# ESP32-S31 register map
Vendor: ESPRESSIF SYSTEMS (SHANGHAI) CO., LTD.; Series: ESP32 S-Series; File version: 1
CPU: RV32IMAFC r0p0, little endian, no MPU, FPU, 0 interrupt priority bits
Address unit: 32 bits
Registers are 32-bit, read-write, reset 0x0 unless marked. A register's access mark holds for its fields unless they carry their own. Offsets are from the block's base; [hi:lo] are bit positions.

## CACHE (part 1 of 3) — CACHE Peripheral
Base 0x2C000000
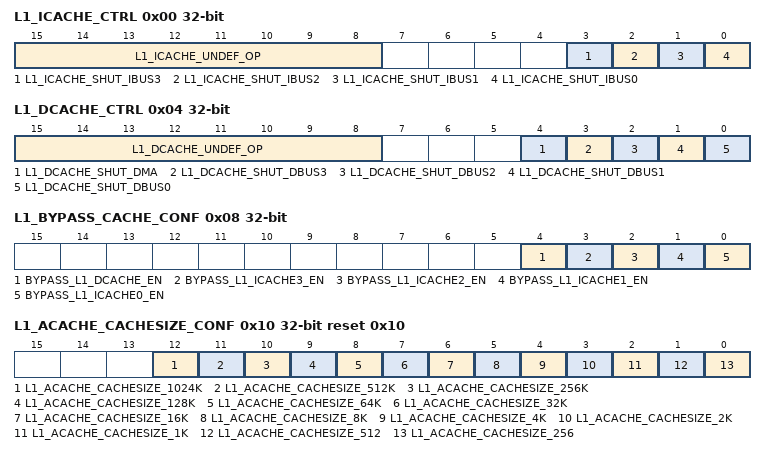
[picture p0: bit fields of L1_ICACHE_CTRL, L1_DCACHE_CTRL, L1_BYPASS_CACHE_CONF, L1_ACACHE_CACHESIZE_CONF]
0x00 L1_ICACHE_CTRL — L1 instruction Cache(L1-ICache) control register
  [15:8] L1_ICACHE_UNDEF_OP — Reserved
  [3] L1_ICACHE_SHUT_IBUS3 — Configures whether to disable IBUS3 to access ROM cache.\\1: Disable\\
  [2] L1_ICACHE_SHUT_IBUS2 — Configures whether to disable IBUS2 to access ROM cache.\\1: Disable\\
  [1] L1_ICACHE_SHUT_IBUS1 — Configures whether to disable IBUS1 to access icache.\\1: Disable\\
  [0] L1_ICACHE_SHUT_IBUS0 — Configures whether to disable IBUS0 to access icache.\\1: Disable\\
0x04 L1_DCACHE_CTRL — L1 data Cache(L1-DCache) control register
  [15:8] L1_DCACHE_UNDEF_OP — Reserved
  [4] L1_DCACHE_SHUT_DMA — The bit is used to disable DMA access L1-DCache, 0: enable, 1: disable
  [3] L1_DCACHE_SHUT_DBUS3 — Configures whether to disable DBUS3 to access ROM cache.\\1: Disable\\
  [2] L1_DCACHE_SHUT_DBUS2 — Configures whether to disable DBUS2 to access ROM cache.\\1: Disable\\
  [1] L1_DCACHE_SHUT_DBUS1 — Configures whether to disable DBUS1 to access dcache.\\1: Disable\\
  [0] L1_DCACHE_SHUT_DBUS0 — Configures whether to disable DBUS0 to access dcache.\\1: Disable\\
0x08 L1_BYPASS_CACHE_CONF — Bypass Cache configure register
  [4] BYPASS_L1_DCACHE_EN — Configures bypass L1-DCache. \\1: Enable\\
  [3] BYPASS_L1_ICACHE3_EN — Reserved
  [2] BYPASS_L1_ICACHE2_EN — Reserved
  [1] BYPASS_L1_ICACHE1_EN — Configures bypass L1-ICache1. \\1: Enable\\
  [0] BYPASS_L1_ICACHE0_EN — Configures bypass L1-ICache0. \\1: Enable\\
0x0C L1_CACHE_ATOMIC_CONF reset 0x1 — L1 Cache atomic feature configure register
  [0] L1_DCACHE_ATOMIC_EN — Configures atomic feature on L1-DCache when multiple cores access L1-DCache. \\1: Enable\\
0x10 L1_ACACHE_CACHESIZE_CONF ro reset 0x10 — L1 Auxiliary Cache CacheSize mode configure register
  [12] L1_ACACHE_CACHESIZE_1024K — The field is used to configure cachesize of L1-ACache as 1024k bytes. This field and all other fields within this register is onehot.
  [11] L1_ACACHE_CACHESIZE_512K — The field is used to configure cachesize of L1-ACache as 512k bytes. This field and all other fields within this register is onehot.
  [10] L1_ACACHE_CACHESIZE_256K — The field is used to configure cachesize of L1-ACache as 256k bytes. This field and all other fields within this register is onehot.
  [9] L1_ACACHE_CACHESIZE_128K — The field is used to configure cachesize of L1-ACache as 128k bytes. This field and all other fields within this register is onehot.
  [8] L1_ACACHE_CACHESIZE_64K — The field is used to configure cachesize of L1-ACache as 64k bytes. This field and all other fields within this register is onehot.
  [7] L1_ACACHE_CACHESIZE_32K — The field is used to configure cachesize of L1-ACache as 32k bytes. This field and all other fields within this register is onehot.
  [6] L1_ACACHE_CACHESIZE_16K — The field is used to configure cachesize of L1-ACache as 16k bytes. This field and all other fields within this register is onehot.
  [5] L1_ACACHE_CACHESIZE_8K — The field is used to configure cachesize of L1-ACache as 8k bytes. This field and all other fields within this register is onehot.
  [4] L1_ACACHE_CACHESIZE_4K — The field is used to configure cachesize of L1-ACache as 4k bytes. This field and all other fields within this register is onehot.
  [3] L1_ACACHE_CACHESIZE_2K — The field is used to configure cachesize of L1-ACache as 2k bytes. This field and all other fields within this register is onehot.
  [2] L1_ACACHE_CACHESIZE_1K — The field is used to configure cachesize of L1-ACache as 1k bytes. This field and all other fields within this register is onehot.
  [1] L1_ACACHE_CACHESIZE_512 — The field is used to configure cachesize of L1-ACache as 512 bytes. This field and all other fields within this register is onehot.
  [0] L1_ACACHE_CACHESIZE_256 — The field is used to configure cachesize of L1-ACache as 256 bytes. This field and all other fields within this register is onehot.
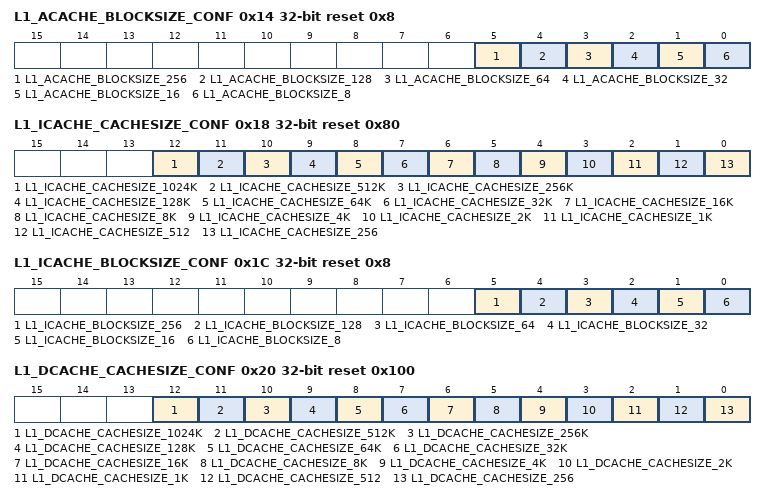
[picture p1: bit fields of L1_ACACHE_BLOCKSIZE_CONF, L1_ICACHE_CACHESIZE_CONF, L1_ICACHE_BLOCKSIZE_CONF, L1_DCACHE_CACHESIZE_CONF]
0x14 L1_ACACHE_BLOCKSIZE_CONF ro reset 0x8 — L1 Auxiliary Cache BlockSize mode configure register
  [5] L1_ACACHE_BLOCKSIZE_256 — The field is used to configureblocksize of L1-ACache as 256 bytes. This field and all other fields within this register is onehot.
  [4] L1_ACACHE_BLOCKSIZE_128 — The field is used to configureblocksize of L1-ACache as 128 bytes. This field and all other fields within this register is onehot.
  [3] L1_ACACHE_BLOCKSIZE_64 — The field is used to configureblocksize of L1-ACache as 64 bytes. This field and all other fields within this register is onehot.
  [2] L1_ACACHE_BLOCKSIZE_32 — The field is used to configureblocksize of L1-ACache as 32 bytes. This field and all other fields within this register is onehot.
  [1] L1_ACACHE_BLOCKSIZE_16 — The field is used to configureblocksize of L1-ACache as 16 bytes. This field and all other fields within this register is onehot.
  [0] L1_ACACHE_BLOCKSIZE_8 — The field is used to configureblocksize of L1-ACache as 8 bytes. This field and all other fields within this register is onehot.
0x18 L1_ICACHE_CACHESIZE_CONF ro reset 0x80 — L1 instruction Cache CacheSize mode configure register
  [12] L1_ICACHE_CACHESIZE_1024K — The field is used to configure cachesize of L1-ICache as 1024k bytes. This field and all other fields within this register is onehot.
  [11] L1_ICACHE_CACHESIZE_512K — The field is used to configure cachesize of L1-ICache as 512k bytes. This field and all other fields within this register is onehot.
  [10] L1_ICACHE_CACHESIZE_256K — The field is used to configure cachesize of L1-ICache as 256k bytes. This field and all other fields within this register is onehot.
  [9] L1_ICACHE_CACHESIZE_128K — The field is used to configure cachesize of L1-ICache as 128k bytes. This field and all other fields within this register is onehot.
  [8] L1_ICACHE_CACHESIZE_64K — The field is used to configure cachesize of L1-ICache as 64k bytes. This field and all other fields within this register is onehot.
  [7] L1_ICACHE_CACHESIZE_32K — The field is used to configure cachesize of L1-ICache as 32k bytes. This field and all other fields within this register is onehot.
  [6] L1_ICACHE_CACHESIZE_16K — The field is used to configure cachesize of L1-ICache as 16k bytes. This field and all other fields within this register is onehot.
  [5] L1_ICACHE_CACHESIZE_8K — The field is used to configure cachesize of L1-ICache as 8k bytes. This field and all other fields within this register is onehot.
  [4] L1_ICACHE_CACHESIZE_4K — The field is used to configure cachesize of L1-ICache as 4k bytes. This field and all other fields within this register is onehot.
  [3] L1_ICACHE_CACHESIZE_2K — The field is used to configure cachesize of L1-ICache as 2k bytes. This field and all other fields within this register is onehot.
  [2] L1_ICACHE_CACHESIZE_1K — The field is used to configure cachesize of L1-ICache as 1k bytes. This field and all other fields within this register is onehot.
  [1] L1_ICACHE_CACHESIZE_512 — The field is used to configure cachesize of L1-ICache as 512 bytes. This field and all other fields within this register is onehot.
  [0] L1_ICACHE_CACHESIZE_256 — The field is used to configure cachesize of L1-ICache as 256 bytes. This field and all other fields within this register is onehot.
0x1C L1_ICACHE_BLOCKSIZE_CONF ro reset 0x8 — L1 instruction Cache BlockSize mode configure register
  [5] L1_ICACHE_BLOCKSIZE_256 — The field is used to configureblocksize of L1-ICache as 256 bytes. This field and all other fields within this register is onehot.
  [4] L1_ICACHE_BLOCKSIZE_128 — The field is used to configureblocksize of L1-ICache as 128 bytes. This field and all other fields within this register is onehot.
  [3] L1_ICACHE_BLOCKSIZE_64 — The field is used to configureblocksize of L1-ICache as 64 bytes. This field and all other fields within this register is onehot.
  [2] L1_ICACHE_BLOCKSIZE_32 — The field is used to configureblocksize of L1-ICache as 32 bytes. This field and all other fields within this register is onehot.
  [1] L1_ICACHE_BLOCKSIZE_16 — The field is used to configureblocksize of L1-ICache as 16 bytes. This field and all other fields within this register is onehot.
  [0] L1_ICACHE_BLOCKSIZE_8 — The field is used to configureblocksize of L1-ICache as 8 bytes. This field and all other fields within this register is onehot.
0x20 L1_DCACHE_CACHESIZE_CONF ro reset 0x100 — L1 data Cache CacheSize mode configure register
  [12] L1_DCACHE_CACHESIZE_1024K — The field is used to configure cachesize of L1-DCache as 1024k bytes. This field and all other fields within this register is onehot.
  [11] L1_DCACHE_CACHESIZE_512K — The field is used to configure cachesize of L1-DCache as 512k bytes. This field and all other fields within this register is onehot.
  [10] L1_DCACHE_CACHESIZE_256K — The field is used to configure cachesize of L1-DCache as 256k bytes. This field and all other fields within this register is onehot.
  [9] L1_DCACHE_CACHESIZE_128K — The field is used to configure cachesize of L1-DCache as 128k bytes. This field and all other fields within this register is onehot.
  [8] L1_DCACHE_CACHESIZE_64K — The field is used to configure cachesize of L1-DCache as 64k bytes. This field and all other fields within this register is onehot.
  [7] L1_DCACHE_CACHESIZE_32K — The field is used to configure cachesize of L1-DCache as 32k bytes. This field and all other fields within this register is onehot.
  [6] L1_DCACHE_CACHESIZE_16K — The field is used to configure cachesize of L1-DCache as 16k bytes. This field and all other fields within this register is onehot.
  [5] L1_DCACHE_CACHESIZE_8K — The field is used to configure cachesize of L1-DCache as 8k bytes. This field and all other fields within this register is onehot.
  [4] L1_DCACHE_CACHESIZE_4K — The field is used to configure cachesize of L1-DCache as 4k bytes. This field and all other fields within this register is onehot.
  [3] L1_DCACHE_CACHESIZE_2K — The field is used to configure cachesize of L1-DCache as 2k bytes. This field and all other fields within this register is onehot.
  [2] L1_DCACHE_CACHESIZE_1K — The field is used to configure cachesize of L1-DCache as 1k bytes. This field and all other fields within this register is onehot.
  [1] L1_DCACHE_CACHESIZE_512 — The field is used to configure cachesize of L1-DCache as 512 bytes. This field and all other fields within this register is onehot.
  [0] L1_DCACHE_CACHESIZE_256 — The field is used to configure cachesize of L1-DCache as 256 bytes. This field and all other fields within this register is onehot.
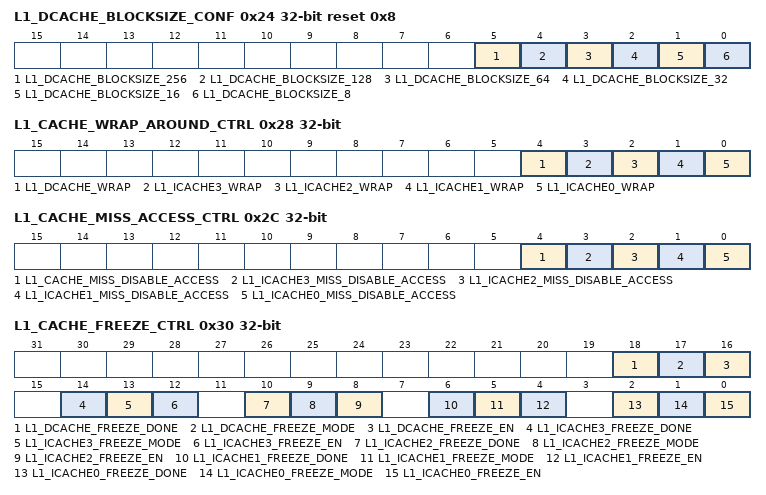
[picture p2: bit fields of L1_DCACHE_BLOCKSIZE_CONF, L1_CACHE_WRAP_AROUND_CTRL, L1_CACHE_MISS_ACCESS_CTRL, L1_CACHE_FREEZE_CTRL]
0x24 L1_DCACHE_BLOCKSIZE_CONF ro reset 0x8 — L1 data Cache BlockSize mode configure register
  [5] L1_DCACHE_BLOCKSIZE_256 — The field is used to configureblocksize of L1-DCache as 256 bytes. This field and all other fields within this register is onehot.
  [4] L1_DCACHE_BLOCKSIZE_128 — The field is used to configureblocksize of L1-DCache as 128 bytes. This field and all other fields within this register is onehot.
  [3] L1_DCACHE_BLOCKSIZE_64 — The field is used to configureblocksize of L1-DCache as 64 bytes. This field and all other fields within this register is onehot.
  [2] L1_DCACHE_BLOCKSIZE_32 — The field is used to configureblocksize of L1-DCache as 32 bytes. This field and all other fields within this register is onehot.
  [1] L1_DCACHE_BLOCKSIZE_16 — The field is used to configureblocksize of L1-DCache as 16 bytes. This field and all other fields within this register is onehot.
  [0] L1_DCACHE_BLOCKSIZE_8 — The field is used to configureblocksize of L1-DCache as 8 bytes. This field and all other fields within this register is onehot.
0x28 L1_CACHE_WRAP_AROUND_CTRL access per field — Cache wrap around control register
  [4] L1_DCACHE_WRAP rw — Configures whether to enable the critical word first function.\\1: Enable\\
  [3] L1_ICACHE3_WRAP ro — Reserved
  [2] L1_ICACHE2_WRAP ro — Reserved
  [1] L1_ICACHE1_WRAP rw — Configures whether to enable the critical word first function.\\1: Enable\\
  [0] L1_ICACHE0_WRAP rw — Configures whether to enable the critical word first function.\\1: Enable\\
0x2C L1_CACHE_MISS_ACCESS_CTRL — Cache wrap around control register
  [4] L1_CACHE_MISS_DISABLE_ACCESS — Configures whether to enable early restart function.\\1: Enable\\
  [3] L1_ICACHE3_MISS_DISABLE_ACCESS — Reserved
  [2] L1_ICACHE2_MISS_DISABLE_ACCESS — Reserved
  [1] L1_ICACHE1_MISS_DISABLE_ACCESS — Configures whether to enable early restart function.\\1: Enable\\
  [0] L1_ICACHE0_MISS_DISABLE_ACCESS — Configures whether to enable early restart function.\\1: Enable\\
0x30 L1_CACHE_FREEZE_CTRL access per field — Cache Freeze control register
  [18] L1_DCACHE_FREEZE_DONE ro — Indicates whether the freeze operation has finished.\\1: Finished\\
  [17] L1_DCACHE_FREEZE_MODE rw — Configures the freeze mode.\\1: Assert hit if a cache miss occurs\\
  [16] L1_DCACHE_FREEZE_EN rw — Configures whether to enable freeze operation. It can be cleared by software.\\1: Enable\\
  [14] L1_ICACHE3_FREEZE_DONE ro — Reserved
  [13] L1_ICACHE3_FREEZE_MODE ro — Reserved
  [12] L1_ICACHE3_FREEZE_EN ro — Reserved
  [10] L1_ICACHE2_FREEZE_DONE ro — Reserved
  [9] L1_ICACHE2_FREEZE_MODE ro — Reserved
  [8] L1_ICACHE2_FREEZE_EN ro — Reserved
  [6] L1_ICACHE1_FREEZE_DONE ro — Indicates whether the freeze operation has finished.\\1: Finished\\
  [5] L1_ICACHE1_FREEZE_MODE rw — Configures the freeze mode.\\1: Assert hit if a cache miss occurs\\
  [4] L1_ICACHE1_FREEZE_EN rw — Configures whether to enable freeze operation. It can be cleared by software.\\1: Enable\\
  [2] L1_ICACHE0_FREEZE_DONE ro — Indicates whether the freeze operation has finished.\\1: Finished\\
  [1] L1_ICACHE0_FREEZE_MODE rw — Configures the freeze mode.\\1: Assert hit if a cache miss occurs\\
  [0] L1_ICACHE0_FREEZE_EN rw — Configures whether to enable freeze operation. It can be cleared by software.\\1: Enable\\
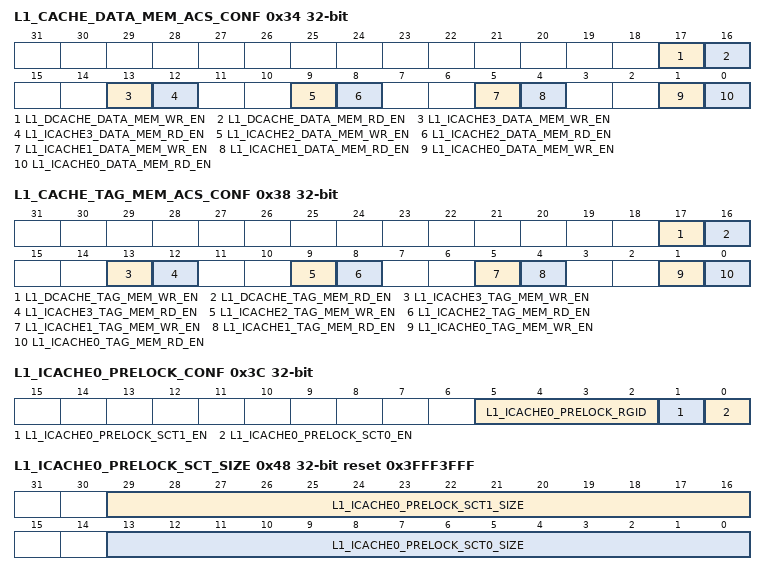
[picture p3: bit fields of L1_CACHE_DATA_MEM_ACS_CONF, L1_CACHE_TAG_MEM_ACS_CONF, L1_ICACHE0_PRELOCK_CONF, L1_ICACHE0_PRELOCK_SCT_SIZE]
0x34 L1_CACHE_DATA_MEM_ACS_CONF — Cache data memory access configure register
  [17] L1_DCACHE_DATA_MEM_WR_EN — Configures whether to enable the configuration bus to write the L1 cache data memory.\\1: Enable\\
  [16] L1_DCACHE_DATA_MEM_RD_EN — Configures whether to enable the configuration bus to read the L1 cache data memory.\\1: Enable\\
  [13] L1_ICACHE3_DATA_MEM_WR_EN — Reserved
  [12] L1_ICACHE3_DATA_MEM_RD_EN — Reserved
  [9] L1_ICACHE2_DATA_MEM_WR_EN — Reserved
  [8] L1_ICACHE2_DATA_MEM_RD_EN — Reserved
  [5] L1_ICACHE1_DATA_MEM_WR_EN — Configures whether to enable the configuration bus to write the L1 cache data memory.\\1: Enable\\
  [4] L1_ICACHE1_DATA_MEM_RD_EN — Configures whether to enable the configuration bus to read the L1 cache data memory.\\1: Enable\\
  [1] L1_ICACHE0_DATA_MEM_WR_EN — Configures whether to enable the configuration bus to write the L1 cache data memory.\\1: Enable\\
  [0] L1_ICACHE0_DATA_MEM_RD_EN — Configures whether to enable the configuration bus to read the L1 cache data memory.\\1: Enable\\
0x38 L1_CACHE_TAG_MEM_ACS_CONF — Cache tag memory access configure register
  [17] L1_DCACHE_TAG_MEM_WR_EN — Configures whether to enable the configuration bus to write the L1 cache tag memory.\\1: Enable\\
  [16] L1_DCACHE_TAG_MEM_RD_EN — Configures whether to enable the configuration bus to read the L1 cache tag memory.\\1: Enable\\
  [13] L1_ICACHE3_TAG_MEM_WR_EN — Reserved
  [12] L1_ICACHE3_TAG_MEM_RD_EN — Reserved
  [9] L1_ICACHE2_TAG_MEM_WR_EN — Reserved
  [8] L1_ICACHE2_TAG_MEM_RD_EN — Reserved
  [5] L1_ICACHE1_TAG_MEM_WR_EN — Configures whether to enable the configuration bus to write the L1 cache tag memory.\\1: Enable\\
  [4] L1_ICACHE1_TAG_MEM_RD_EN — Configures whether to enable the configuration bus to read the L1 cache tag memory.\\1: Enable\\
  [1] L1_ICACHE0_TAG_MEM_WR_EN — Configures whether to enable the configuration bus to write the L1 cache tag memory.\\1: Enable\\
  [0] L1_ICACHE0_TAG_MEM_RD_EN — Configures whether to enable the configuration bus to read the L1 cache tag memory.\\1: Enable\\
0x3C L1_ICACHE0_PRELOCK_CONF — L1 instruction Cache 0 prelock configure register
  [5:2] L1_ICACHE0_PRELOCK_RGID — Configures the gid of l1 icache0 prelock.
  [1] L1_ICACHE0_PRELOCK_SCT1_EN — Configures whether to enable the prelocking function in Section 1 of icache.\\1: Enable\\
  [0] L1_ICACHE0_PRELOCK_SCT0_EN — Configures whether to enable the prelocking function in Section 0 of icache.\\1: Enable\\
0x40 L1_ICACHE0_PRELOCK_SCT0_ADDR — L1 instruction Cache 0 prelock section0 address configure register
  [31:0] L1_ICACHE0_PRELOCK_SCT0_ADDR — Configures the start address of the first section of prelock on L1-ICache0, which should be used together with L1_ICACHE0_PRELOCK_SCT0_SIZE_REG
0x44 L1_ICACHE0_PRELOCK_SCT1_ADDR — L1 instruction Cache 0 prelock section1 address configure register
  [31:0] L1_ICACHE0_PRELOCK_SCT1_ADDR — Configures the start address of the second section of prelock on L1-ICache0, which should be used together with L1_ICACHE0_PRELOCK_SCT1_SIZE_REG
0x48 L1_ICACHE0_PRELOCK_SCT_SIZE reset 0x3FFF3FFF — L1 instruction Cache 0 prelock section size configure register
  [29:16] L1_ICACHE0_PRELOCK_SCT1_SIZE — Configures the size of the second section of prelock on L1-ICache0, which should be used together with L1_ICACHE0_PRELOCK_SCT1_ADDR_REG
  [13:0] L1_ICACHE0_PRELOCK_SCT0_SIZE — Configures the size of the first section of prelock on L1-ICache0, which should be used together with L1_ICACHE0_PRELOCK_SCT0_ADDR_REG
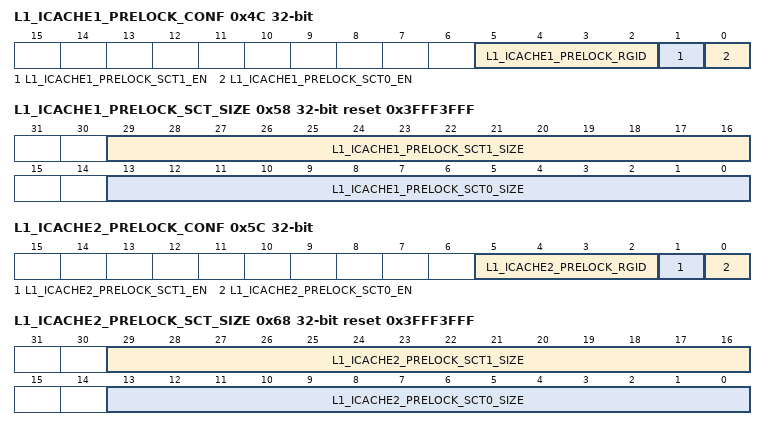
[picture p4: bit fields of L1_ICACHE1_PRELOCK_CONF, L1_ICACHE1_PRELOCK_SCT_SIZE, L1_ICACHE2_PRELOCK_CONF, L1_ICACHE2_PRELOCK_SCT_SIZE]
0x4C L1_ICACHE1_PRELOCK_CONF — L1 instruction Cache 1 prelock configure register
  [5:2] L1_ICACHE1_PRELOCK_RGID — Configures the gid of l1 icache1 prelock.
  [1] L1_ICACHE1_PRELOCK_SCT1_EN — Configures whether to enable the prelocking function in Section 1 of icache.\\1: Enable\\
  [0] L1_ICACHE1_PRELOCK_SCT0_EN — Configures whether to enable the prelocking function in Section 0 of icache.\\1: Enable\\
0x50 L1_ICACHE1_PRELOCK_SCT0_ADDR — L1 instruction Cache 1 prelock section0 address configure register
  [31:0] L1_ICACHE1_PRELOCK_SCT0_ADDR — Those bits are used to configure the start address of the first section of prelock on L1-ICache1, which should be used together with L1_ICACHE1_PRELOCK_SCT0_SIZE_REG
0x54 L1_ICACHE1_PRELOCK_SCT1_ADDR — L1 instruction Cache 1 prelock section1 address configure register
  [31:0] L1_ICACHE1_PRELOCK_SCT1_ADDR — Configures the start address of the second section of prelock on L1-ICache1, which should be used together with L1_ICACHE1_PRELOCK_SCT1_SIZE_REG
0x58 L1_ICACHE1_PRELOCK_SCT_SIZE reset 0x3FFF3FFF — L1 instruction Cache 1 prelock section size configure register
  [29:16] L1_ICACHE1_PRELOCK_SCT1_SIZE — Configures the size of the second section of prelock on L1-ICache1, which should be used together with L1_ICACHE1_PRELOCK_SCT1_ADDR_REG
  [13:0] L1_ICACHE1_PRELOCK_SCT0_SIZE — Configures the size of the first section of prelock on L1-ICache1, which should be used together with L1_ICACHE1_PRELOCK_SCT0_ADDR_REG
0x5C L1_ICACHE2_PRELOCK_CONF ro — L1 instruction Cache 2 prelock configure register
  [5:2] L1_ICACHE2_PRELOCK_RGID — Configures the gid of l1 icache2 prelock.
  [1] L1_ICACHE2_PRELOCK_SCT1_EN — Configures the second section of prelock function on L1-ICache2.
  [0] L1_ICACHE2_PRELOCK_SCT0_EN — Configures the first section of prelock function on L1-ICache2.
0x60 L1_ICACHE2_PRELOCK_SCT0_ADDR ro — L1 instruction Cache 2 prelock section0 address configure register
  [31:0] L1_ICACHE2_PRELOCK_SCT0_ADDR — Configures the start address of the first section of prelock on L1-ICache2, which should be used together with L1_ICACHE2_PRELOCK_SCT0_SIZE_REG
0x64 L1_ICACHE2_PRELOCK_SCT1_ADDR ro — L1 instruction Cache 2 prelock section1 address configure register
  [31:0] L1_ICACHE2_PRELOCK_SCT1_ADDR — Configures the start address of the second section of prelock on L1-ICache2, which should be used together with L1_ICACHE2_PRELOCK_SCT1_SIZE_REG
0x68 L1_ICACHE2_PRELOCK_SCT_SIZE ro reset 0x3FFF3FFF — L1 instruction Cache 2 prelock section size configure register
  [29:16] L1_ICACHE2_PRELOCK_SCT1_SIZE — Configures the size of the second section of prelock on L1-ICache2, which should be used together with L1_ICACHE2_PRELOCK_SCT1_ADDR_REG
  [13:0] L1_ICACHE2_PRELOCK_SCT0_SIZE — Configures the size of the first section of prelock on L1-ICache2, which should be used together with L1_ICACHE2_PRELOCK_SCT0_ADDR_REG
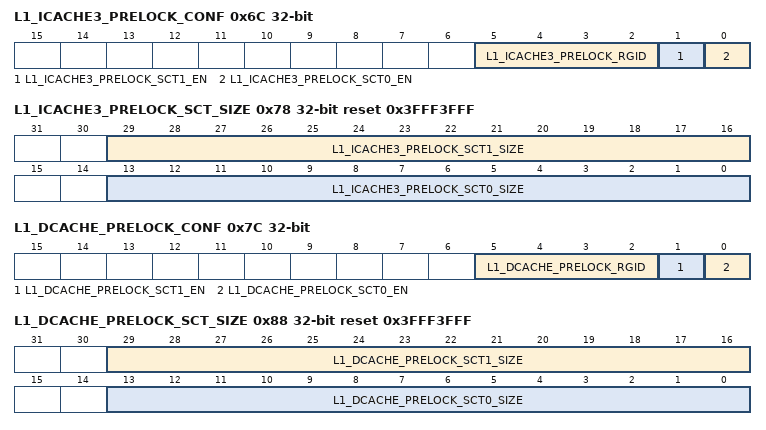
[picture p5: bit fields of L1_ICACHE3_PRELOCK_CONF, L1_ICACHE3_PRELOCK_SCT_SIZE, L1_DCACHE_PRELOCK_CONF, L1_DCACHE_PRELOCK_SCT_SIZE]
0x6C L1_ICACHE3_PRELOCK_CONF ro — L1 instruction Cache 3 prelock configure register
  [5:2] L1_ICACHE3_PRELOCK_RGID — Configures the gid of l1 icache3 prelock.
  [1] L1_ICACHE3_PRELOCK_SCT1_EN — Configures the second section of prelock function on L1-ICache3.
  [0] L1_ICACHE3_PRELOCK_SCT0_EN — Configures the first section of prelock function on L1-ICache3.
0x70 L1_ICACHE3_PRELOCK_SCT0_ADDR ro — L1 instruction Cache 3 prelock section0 address configure register
  [31:0] L1_ICACHE3_PRELOCK_SCT0_ADDR — Configures the start address of the first section of prelock on L1-ICache3, which should be used together with L1_ICACHE3_PRELOCK_SCT0_SIZE_REG
0x74 L1_ICACHE3_PRELOCK_SCT1_ADDR ro — L1 instruction Cache 3 prelock section1 address configure register
  [31:0] L1_ICACHE3_PRELOCK_SCT1_ADDR — Configures the start address of the second section of prelock on L1-ICache3, which should be used together with L1_ICACHE3_PRELOCK_SCT1_SIZE_REG
0x78 L1_ICACHE3_PRELOCK_SCT_SIZE ro reset 0x3FFF3FFF — L1 instruction Cache 3 prelock section size configure register
  [29:16] L1_ICACHE3_PRELOCK_SCT1_SIZE — Configures the size of the second section of prelock on L1-ICache3, which should be used together with L1_ICACHE3_PRELOCK_SCT1_ADDR_REG
  [13:0] L1_ICACHE3_PRELOCK_SCT0_SIZE — Configures the size of the first section of prelock on L1-ICache3, which should be used together with L1_ICACHE3_PRELOCK_SCT0_ADDR_REG
0x7C L1_DCACHE_PRELOCK_CONF — L1 data Cache prelock configure register
  [5:2] L1_DCACHE_PRELOCK_RGID — Configures the gid of l1 dcache prelock.
  [1] L1_DCACHE_PRELOCK_SCT1_EN — Configures whether to enable the prelocking function in Section 1 of dcache.\\1: Enable\\
  [0] L1_DCACHE_PRELOCK_SCT0_EN — Configures whether to enable the prelocking function in Section 0 of dcache.\\1: Enable\\
0x80 L1_DCACHE_PRELOCK_SCT0_ADDR — L1 data Cache prelock section0 address configure register
  [31:0] L1_DCACHE_PRELOCK_SCT0_ADDR — Configures the start address of the first section of prelock on L1-DCache, which should be used together with L1_DCACHE_PRELOCK_SCT0_SIZE_REG
0x84 L1_DCACHE_PRELOCK_SCT1_ADDR — L1 data Cache prelock section1 address configure register
  [31:0] L1_DCACHE_PRELOCK_SCT1_ADDR — Configures the start address of the second section of prelock on L1-DCache, which should be used together with L1_DCACHE_PRELOCK_SCT1_SIZE_REG
0x88 L1_DCACHE_PRELOCK_SCT_SIZE reset 0x3FFF3FFF — L1 data Cache prelock section size configure register
  [29:16] L1_DCACHE_PRELOCK_SCT1_SIZE — Configures the size of the second section of prelock on L1-DCache, which should be used together with L1_DCACHE_PRELOCK_SCT1_ADDR_REG
  [13:0] L1_DCACHE_PRELOCK_SCT0_SIZE — Configures the size of the first section of prelock on L1-DCache, which should be used together with L1_DCACHE_PRELOCK_SCT0_ADDR_REG
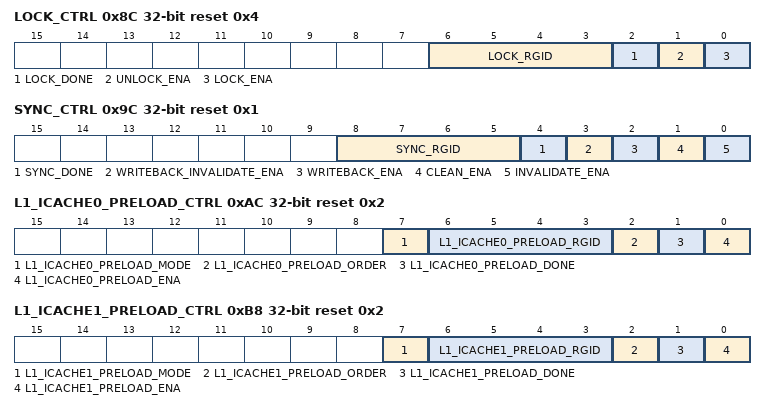
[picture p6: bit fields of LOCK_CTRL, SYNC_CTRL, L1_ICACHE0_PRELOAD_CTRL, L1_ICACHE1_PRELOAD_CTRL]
0x8C LOCK_CTRL access per field reset 0x4 — Lock-class (manual lock) operation control register
  [6:3] LOCK_RGID rw — Configures the gid of cache lock/unlock.
  [2] LOCK_DONE ro — Indicates whether the unlocking or the locking operation has finished.\\1: Finished\\
  [1] UNLOCK_ENA rw — Configures whether to enable unlock operation. It will be cleared by hardware after the unlocking operation is done.\\1: Enable\\
  [0] LOCK_ENA rw — Configures whether to enable lock operation. It will be cleared by hardware after the locking operation is done.\\1: Enable\\
0x90 LOCK_MAP — Lock (manual lock) map configure register
  [5:0] LOCK_MAP — Configures caches in the two-level cache structure will apply this lock/unlock operation. \\Other bits: Reserved\\
0x94 LOCK_ADDR — Lock (manual lock) address configure register
  [31:0] LOCK_ADDR — Configures the start address of the lock/unlock operation, which should be used together with CACHE_LOCK_SIZE_REG
0x98 LOCK_SIZE — Lock (manual lock) size configure register
  [15:0] LOCK_SIZE — Configures the size of the lock/unlock operation, which should be used together with CACHE_LOCK_ADDR_REG
0x9C SYNC_CTRL access per field reset 0x1 — Sync-class operation control register
  [8:5] SYNC_RGID rw — Configures the gid of cache sync operation (invalidate, clean, writeback, writeback_invalidate)
  [4] SYNC_DONE ro — Indicates whether the synchronization operation has finished.\\1: Finished\\
  [3] WRITEBACK_INVALIDATE_ENA rw — Configures whether to enable the write-back invalidation operation. Hardware will clear it once the operation has finished.\\1: Enable\\
  [2] WRITEBACK_ENA rw — Configures whether to enable the write-back operation. Hardware will clear it once the operation has finished.\\1: Enable\\
  [1] CLEAN_ENA rw — Configures whether to enable the clean operation. Hardware will clear it once the operation has finished.\\1: Enable\\
  [0] INVALIDATE_ENA rw — Configures whether to enable the invalidation operation. Hardware will clear it once the operation has finished.\\Please note that this field, along with the other fields (CLEAN_ENA, WRITEBACK_ENA, WRITEBACK_INVALIDATE_ENA), is mutually exclusive. In other words, only one of these fields can be set to 1 at any given time. \\
0xA0 SYNC_MAP reset 0x1F — Sync map configure register
  [5:0] SYNC_MAP — Configures which cache to perform the locking or the unlocking operation.\\Other bits: Reserved\\
0xA4 SYNC_ADDR — Sync address configure register
  [31:0] SYNC_ADDR — Configures the start address of the sync operation, which should be used together with CACHE_SYNC_SIZE_REG
0xA8 SYNC_SIZE — Sync size configure register
  [27:0] SYNC_SIZE — Configures the size of the sync operation, which should be used together with CACHE_SYNC_ADDR_REG
0xAC L1_ICACHE0_PRELOAD_CTRL access per field reset 0x2 — L1 instruction Cache 0 preload-operation control register
  [7] L1_ICACHE0_PRELOAD_MODE rw — Configures the mode of l1 icache0 preload, 0: load data from next level memory, 1: not load data from next level memory.
  [6:3] L1_ICACHE0_PRELOAD_RGID rw — Configures the gid of l1 icache0 preload.
  [2] L1_ICACHE0_PRELOAD_ORDER rw — Configures the direction of the preloading operation.\\1: Descending\\
  [1] L1_ICACHE0_PRELOAD_DONE ro — Represents whether the preloading operation has finished.\\1: Finished\\
  [0] L1_ICACHE0_PRELOAD_ENA rw — Configures whether to enable the preloading operation in icache0. Hardware will clear it once the operation has finished.\\1: Enable\\
0xB0 L1_ICACHE0_PRELOAD_ADDR — icache0 preload address configuration register
  [31:0] L1_ICACHE0_PRELOAD_ADDR — Configures the start address of preload on L1-ICache0, which should be used together with L1_ICACHE0_PRELOAD_SIZE_REG
0xB4 L1_ICACHE0_PRELOAD_SIZE — L1 instruction Cache 0 preload size configure register
  [13:0] L1_ICACHE0_PRELOAD_SIZE — Configures the size of the first section of prelock on L1-ICache0, which should be used together with L1_ICACHE0_PRELOAD_ADDR_REG
0xB8 L1_ICACHE1_PRELOAD_CTRL access per field reset 0x2 — L1 instruction Cache 1 preload-operation control register
  [7] L1_ICACHE1_PRELOAD_MODE rw — Configures the mode of l1 icache1 preload, 0: load data from next level memory, 1: not load data from next level memory.
  [6:3] L1_ICACHE1_PRELOAD_RGID rw — Configures the gid of l1 icache1 preload.
  [2] L1_ICACHE1_PRELOAD_ORDER rw — Configures the direction of the preloading operation.\\1: Descending\\
  [1] L1_ICACHE1_PRELOAD_DONE ro — Represents whether the preloading operation has finished.\\1: Finished\\
  [0] L1_ICACHE1_PRELOAD_ENA rw — Configures whether to enable the preloading operation in icache1. Hardware will clear it once the operation has finished.\\1: Enable\\
0xBC L1_ICACHE1_PRELOAD_ADDR — icache1 preload address configuration register
  [31:0] L1_ICACHE1_PRELOAD_ADDR — Configures the start address of preload on L1-ICache1, which should be used together with L1_ICACHE1_PRELOAD_SIZE_REG
0xC0 L1_ICACHE1_PRELOAD_SIZE — L1 instruction Cache 1 preload size configure register
  [13:0] L1_ICACHE1_PRELOAD_SIZE — Configures the size of the first section of prelock on L1-ICache1, which should be used together with L1_ICACHE1_PRELOAD_ADDR_REG
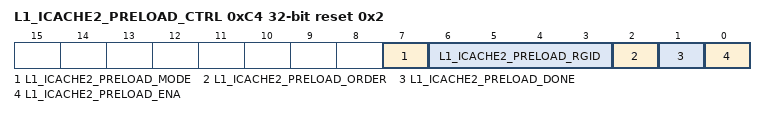
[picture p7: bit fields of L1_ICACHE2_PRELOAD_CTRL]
0xC4 L1_ICACHE2_PRELOAD_CTRL access per field reset 0x2 — L1 instruction Cache 2 preload-operation control register
  [7] L1_ICACHE2_PRELOAD_MODE ro — Configures the mode of l1 icache2 preload, 0: load data from next level memory, 1: not load data from next level memory.
  [6:3] L1_ICACHE2_PRELOAD_RGID ro — Configures the gid of l1 icache2 preload.
  [2] L1_ICACHE2_PRELOAD_ORDER ro — Configures the direction of preload operation. 0: ascending, 1: descending.
  [1] L1_ICACHE2_PRELOAD_DONE ro — The bit is used to indicate whether preload operation is finished or not. 0: not finished. 1: finished.
  [0] L1_ICACHE2_PRELOAD_ENA rw — Configures preload operation on L1-ICache2. It will be cleared by hardware automatically after preload operation is done.
0xC8 L1_ICACHE2_PRELOAD_ADDR ro — L1 instruction Cache 2 preload address configure register
  [31:0] L1_ICACHE2_PRELOAD_ADDR — Configures the start address of preload on L1-ICache2, which should be used together with L1_ICACHE2_PRELOAD_SIZE_REG
0xCC L1_ICACHE2_PRELOAD_SIZE ro — L1 instruction Cache 2 preload size configure register
  [13:0] L1_ICACHE2_PRELOAD_SIZE — Configures the size of the first section of prelock on L1-ICache2, which should be used together with L1_ICACHE2_PRELOAD_ADDR_REG
